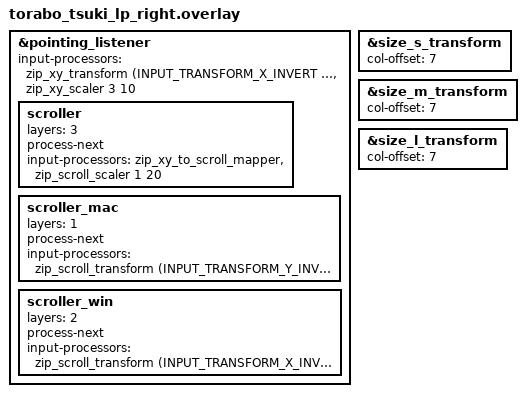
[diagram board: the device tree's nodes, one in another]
#include "torabo_tsuki_lp.dtsi"
#include <input/processors.dtsi>
#include <dt-bindings/zmk/input_transform.h>
#include <dt-bindings/zmk/keys.h>

&pointing_listener {
    input-processors = <
        &zip_xy_transform (INPUT_TRANSFORM_X_INVERT | INPUT_TRANSFORM_Y_INVERT)
        &zip_xy_scaler 3 10
    >;

    scroller {
        layers = <3>;
        // スクロールレイヤー共通の変換・スケーリング（軸反転は OS 別レイヤー側で行う）
        process-next;
        input-processors = <
            &zip_xy_to_scroll_mapper
            &zip_scroll_scaler 1 20
        >;
    };

    scroller_mac {
        // Mac(layer 1): ナチュラルスクロール向けに Y を反転
        layers = <1>;
        process-next;
        input-processors = <&zip_scroll_transform (INPUT_TRANSFORM_Y_INVERT)>;
    };

    scroller_win {
        // Windows(layer 2): X を反転
        layers = <2>;
        process-next;
        input-processors = <&zip_scroll_transform (INPUT_TRANSFORM_X_INVERT)>;
    };
};

&size_s_transform {
    col-offset = <7>;
};

&size_m_transform {
    col-offset = <7>;
};

&size_l_transform {
    col-offset = <7>;
};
